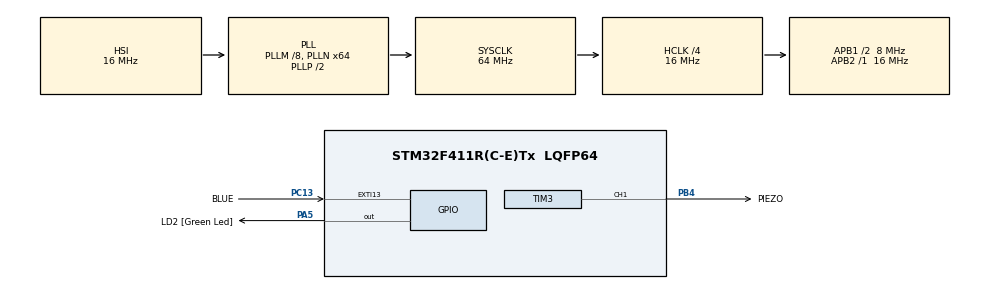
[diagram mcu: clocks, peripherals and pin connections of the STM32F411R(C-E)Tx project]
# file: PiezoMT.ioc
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FREERTOS.Tasks01=mainThread,24,128,osMainThread,Default,NULL,Dynamic,NULL,NULL;ButtonThread,33,128,osButtonThread,Default,NULL,Dynamic,NULL,NULL
FREERTOS.configUSE_NEWLIB_REENTRANT=1
Mcu.Family=STM32F4
Mcu.Name=STM32F411R(C-E)Tx
Mcu.Package=LQFP64
NVIC.EXTI15_10_IRQn=true\:6\:0\:true\:false\:true\:true\:true\:true\:true
NVIC.PriorityGroup=NVIC_PRIORITYGROUP_4
NVIC.RCC_IRQn=true\:5\:0\:false\:false\:true\:true\:true\:false\:true
NVIC.TIM1_UP_TIM10_IRQn=true\:15\:0\:false\:false\:true\:false\:false\:true\:true
NVIC.TIM3_IRQn=true\:5\:0\:false\:false\:true\:true\:true\:true\:true
NVIC.TimeBase=TIM1_UP_TIM10_IRQn
NVIC.TimeBaseIP=TIM1
PA13.GPIO_Label=TMS
PA13.Mode=Serial_Wire
PA13.Signal=SYS_JTMS-SWDIO
PA14.GPIO_Label=TCK
PA14.Mode=Serial_Wire
PA14.Signal=SYS_JTCK-SWCLK
PA2.GPIO_Label=USART_TX
PA2.Signal=USART2_TX
PA3.GPIO_Label=USART_RX
PA3.Signal=USART2_RX
PA5.GPIO_Label=LD2 [Green Led]
PA5.Signal=GPIO_Output
PB3.GPIO_Label=SWO
PB3.Signal=SYS_JTDO-SWO
PB4.GPIO_Label=PIEZO
PB4.Signal=S_TIM3_CH1
PC13-ANTI_TAMP.GPIO_Label=BLUE
PC13-ANTI_TAMP.GPIO_ModeDefaultEXTI=GPIO_MODE_IT_FALLING
PC13-ANTI_TAMP.Signal=GPXTI13
PC14-OSC32_IN.Signal=RCC_OSC32_IN
PC15-OSC32_OUT.Signal=RCC_OSC32_OUT
PH0\ -\ OSC_IN.Mode=HSE-External-Oscillator
PH0\ -\ OSC_IN.Signal=RCC_OSC_IN
PH1\ -\ OSC_OUT.Mode=HSE-External-Oscillator
PH1\ -\ OSC_OUT.Signal=RCC_OSC_OUT
ProjectManager.HeapSize=0x200
ProjectManager.StackSize=0x400
ProjectManager.TargetToolchain=STM32CubeIDE
RCC.48MHZClocksFreq_Value=32000000
RCC.AHBCLKDivider=RCC_SYSCLK_DIV4
RCC.AHBFreq_Value=16000000
RCC.APB1CLKDivider=RCC_HCLK_DIV2
RCC.APB1Freq_Value=8000000
RCC.APB1TimFreq_Value=16000000
RCC.APB2Freq_Value=16000000
RCC.APB2TimFreq_Value=16000000
RCC.CortexFreq_Value=16000000
RCC.FLatency-AdvancedSettings=FLASH_LATENCY_0
RCC.HCLKFreq_Value=16000000
RCC.HSE_VALUE=8000000
RCC.HSI_VALUE=16000000
RCC.LSE_VALUE=32768
RCC.PLLM=8
RCC.PLLN=64
RCC.SYSCLKFreq_VALUE=64000000
RCC.SYSCLKSource=RCC_SYSCLKSOURCE_PLLCLK
RCC.VCOOutputFreq_Value=128000000
SH.S_TIM3_CH1.0=TIM3_CH1,PWM Generation1 CH1
TIM3.AutoReloadPreload=TIM_AUTORELOAD_PRELOAD_ENABLE
TIM3.Channel-PWM\ Generation1\ CH1=TIM_CHANNEL_1
TIM3.CounterMode=TIM_COUNTERMODE_UP
TIM3.Period=1135
TIM3.Prescaler=15
TIM3.Pulse-PWM\ Generation1\ CH1=1135
TIM3.TIM_MasterOutputTrigger=TIM_TRGO_UPDATE
VP_FREERTOS_VS_CMSIS_V2.Mode=CMSIS_V2
VP_SYS_VS_tim1.Mode=TIM1
VP_TIM3_VS_ClockSourceINT.Mode=Internal
board=NUCLEO-F411RE

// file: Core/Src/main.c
/* USER CODE BEGIN Header */
/**
  ******************************************************************************
  * @file           : main.c
  * @brief          : Main program body
  ******************************************************************************
  * @attention
  *
  * Copyright (c) 2024 STMicroelectronics.
  * All rights reserved.
  *
  * This software is licensed under terms that can be found in the LICENSE file
  * in the root directory of this software component.
  * If no LICENSE file comes with this software, it is provided AS-IS.
  *
  ******************************************************************************
  */
/* USER CODE END Header */
#include "main.h"
#include "cmsis_os.h"
#include "tim.h"
#include "gpio.h"

/* USER CODE BEGIN Includes */
#include <stdbool.h>

/* USER CODE END Includes */

/* USER CODE BEGIN PV */
static bool button = true;
static uint32_t volume = 0;
static bool up = true;

/* USER CODE END PV */

void SystemClock_Config(void);
void MX_FREERTOS_Init(void);
/* USER CODE BEGIN PFP */
void timerSetVolume(uint32_t vol);

/* USER CODE END PFP */

int main(void)
{

  /* MCU Configuration--------------------------------------------------------*/

  /* Reset of all peripherals, Initializes the Flash interface and the Systick. */
  HAL_Init();

  /* Configure the system clock */
  SystemClock_Config();

  /* Initialize all configured peripherals */
  MX_GPIO_Init();
  MX_TIM3_Init();
  /* USER CODE BEGIN 2 */

  //HAL_TIM_Base_Start(&htim3); //need timer oc start
  //HAL_TIM_OC_Start(&htim3, TIM_CHANNEL_1);

  /* USER CODE END 2 */

  /* Init scheduler */
  //osKernelInitialize();

  /* Call init function for freertos objects (in cmsis_os2.c) */
  //MX_FREERTOS_Init();

  /* Start scheduler */
  //osKernelStart();

  /* We should never get here as control is now taken by the scheduler */

  /* Infinite loop */
  /* USER CODE BEGIN WHILE */
  //HAL_TIM_OC_Start(&htim3, TIM_CHANNEL_1);
  HAL_TIM_PWM_Start(&htim3, TIM_CHANNEL_1);
  int32_t CH1_DC = 0;

  while (1)
  {
	  //timerSetVolume(volume);
	  /*if(volume < 1100){
		  volume += 5;
	  }
	  __HAL_TIM_SET_COMPARE(&htim3,TIM_CHANNEL_1, (volume));
	  //timerSetVolume(volume);
	  HAL_Delay(200);*/

	  /*if(button == true){
		  TIM3->CCR1 = CH1_DC;
		  CH1_DC += 70;
		  HAL_Delay(300);
	  }
	  else {
		  TIM3->CCR1 = CH1_DC;
		  CH1_DC -= 70;
		  HAL_Delay(300);
	  }
		  /*HAL_TIM_PWM_Start(&htim3, TIM_CHANNEL_1);
		  HAL_Delay(200);
		  HAL_TIM_PWM_Stop(&htim3, TIM_CHANNEL_1);
		  HAL_Delay(200);
		  }*/

    /* USER CODE END WHILE */

  }
}

void SystemClock_Config(void)
{
  RCC_OscInitTypeDef RCC_OscInitStruct = {0};
  RCC_ClkInitTypeDef RCC_ClkInitStruct = {0};

  /** Configure the main internal regulator output voltage
  */
  __HAL_RCC_PWR_CLK_ENABLE();
  __HAL_PWR_VOLTAGESCALING_CONFIG(PWR_REGULATOR_VOLTAGE_SCALE1);

  /** Initializes the RCC Oscillators according to the specified parameters
  * in the RCC_OscInitTypeDef structure.
  */
  RCC_OscInitStruct.OscillatorType = RCC_OSCILLATORTYPE_HSI;
  RCC_OscInitStruct.HSIState = RCC_HSI_ON;
  RCC_OscInitStruct.HSICalibrationValue = RCC_HSICALIBRATION_DEFAULT;
  RCC_OscInitStruct.PLL.PLLState = RCC_PLL_ON;
  RCC_OscInitStruct.PLL.PLLSource = RCC_PLLSOURCE_HSI;
  RCC_OscInitStruct.PLL.PLLM = 8;
  RCC_OscInitStruct.PLL.PLLN = 64;
  RCC_OscInitStruct.PLL.PLLP = RCC_PLLP_DIV2;
  RCC_OscInitStruct.PLL.PLLQ = 4;
  if (HAL_RCC_OscConfig(&RCC_OscInitStruct) != HAL_OK)
  {
    Error_Handler();
  }

  /** Initializes the CPU, AHB and APB buses clocks
  */
  RCC_ClkInitStruct.ClockType = RCC_CLOCKTYPE_HCLK|RCC_CLOCKTYPE_SYSCLK
                              |RCC_CLOCKTYPE_PCLK1|RCC_CLOCKTYPE_PCLK2;
  RCC_ClkInitStruct.SYSCLKSource = RCC_SYSCLKSOURCE_PLLCLK;
  RCC_ClkInitStruct.AHBCLKDivider = RCC_SYSCLK_DIV4;
  RCC_ClkInitStruct.APB1CLKDivider = RCC_HCLK_DIV2;
  RCC_ClkInitStruct.APB2CLKDivider = RCC_HCLK_DIV1;

  if (HAL_RCC_ClockConfig(&RCC_ClkInitStruct, FLASH_LATENCY_0) != HAL_OK)
  {
    Error_Handler();
  }
}

/* USER CODE BEGIN 4 */
void HAL_GPIO_EXTI_Callback(uint16_t GPIO_Pin)
{
  /* Prevent unused argument(s) compilation warning */
  UNUSED(GPIO_Pin);
  /* NOTE: This function Should not be modified, when the callback is needed,
           the HAL_GPIO_EXTI_Callback could be implemented in the user file
   */
  if(GPIO_Pin == BLUE_Pin){
	  if(up == false){
		  volume -= 5;
	  } else if(up == true){
		  volume += 5;
	  }
	  if(volume == 0){
		  up = true;
	  }
	  if(volume == 50){
		  up = false;
	  }
	  __HAL_TIM_SET_COMPARE(&htim3,TIM_CHANNEL_1, (volume));
  }

  /*if(button == true){
	  button = false;
  } else if(button == false)
	  button = true;*/
}

/* USER CODE END 4 */

void HAL_TIM_PeriodElapsedCallback(TIM_HandleTypeDef *htim)
{
  if (htim->Instance == TIM1) {
    HAL_IncTick();
  }
  /* USER CODE BEGIN Callback 1 */
  /*else if (htim->Instance == TIM3){
  	HAL_GPIO_TogglePin(PIEZO_GPIO_Port, PIEZO_Pin);
  }*/

  /* USER CODE END Callback 1 */
}

void Error_Handler(void)
{
  __disable_irq();
  while (1)
  {
  }
}
